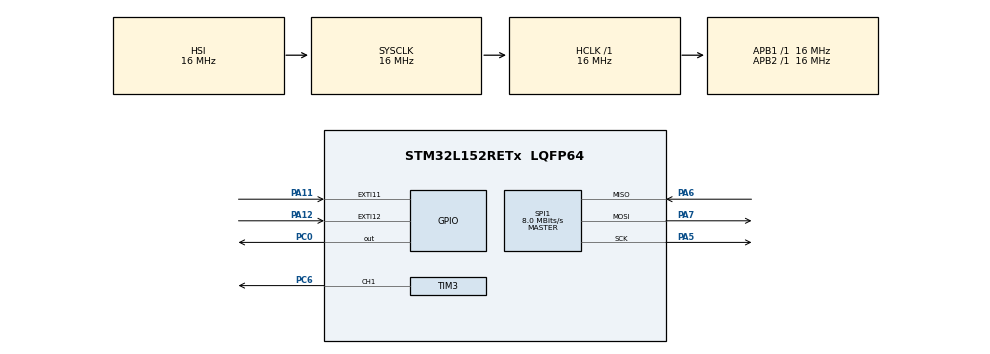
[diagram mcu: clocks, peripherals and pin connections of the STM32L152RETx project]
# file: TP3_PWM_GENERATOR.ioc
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Mcu.Family=STM32L1
Mcu.Name=STM32L152RETx
Mcu.Package=LQFP64
NVIC.EXTI15_10_IRQn=true\:0\:0\:false\:false\:true\:true\:true\:true
NVIC.PriorityGroup=NVIC_PRIORITYGROUP_4
NVIC.TIM2_IRQn=true\:0\:0\:false\:false\:true\:true\:true\:true
NVIC.TIM3_IRQn=true\:0\:0\:false\:false\:true\:true\:true\:true
PA11.Signal=GPXTI11
PA12.Signal=GPXTI12
PA5.Mode=Full_Duplex_Master
PA5.Signal=SPI1_SCK
PA6.Mode=Full_Duplex_Master
PA6.Signal=SPI1_MISO
PA7.Mode=Full_Duplex_Master
PA7.Signal=SPI1_MOSI
PC0.Signal=GPIO_Output
PC6.Signal=S_TIM3_CH1
ProjectManager.HeapSize=0x200
ProjectManager.StackSize=0x400
ProjectManager.TargetToolchain=STM32CubeIDE
RCC.AHBFreq_Value=16000000
RCC.APB1Freq_Value=16000000
RCC.APB1TimFreq_Value=16000000
RCC.APB2Freq_Value=16000000
RCC.APB2TimFreq_Value=16000000
RCC.HCLKFreq_Value=16000000
RCC.HSE_VALUE=24000000
RCC.HSI_VALUE=16000000
RCC.LSE_VALUE=32768
RCC.MSI_VALUE=2097000
RCC.SYSCLKFreq_VALUE=16000000
RCC.SYSCLKSource=RCC_SYSCLKSOURCE_HSI
RCC.VCOOutputFreq_Value=48000000
SH.S_TIM3_CH1.0=TIM3_CH1,PWM Generation1 CH1
SPI1.CalculateBaudRate=8.0 MBits/s
SPI1.Direction=SPI_DIRECTION_2LINES
SPI1.Mode=SPI_MODE_MASTER
SPI1.VirtualType=VM_MASTER
TIM2.AutoReloadPreload=TIM_AUTORELOAD_PRELOAD_ENABLE
TIM2.Period=16000-1
TIM2.Prescaler=1000-1
TIM3.AutoReloadPreload=TIM_AUTORELOAD_PRELOAD_ENABLE
TIM3.Channel-PWM\ Generation1\ CH1=TIM_CHANNEL_1
TIM3.Period=1000-1
TIM3.Prescaler=64-1
TIM3.Pulse-PWM\ Generation1\ CH1=500
VP_TIM2_VS_ClockSourceINT.Mode=Internal
VP_TIM3_VS_ClockSourceINT.Mode=Internal
board=custom

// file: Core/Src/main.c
/* USER CODE BEGIN Header */
/**
  ******************************************************************************
  * @file           : main.c
  * @brief          : Main program body
  ******************************************************************************
  * @attention
  *
  * Copyright (c) 2025 STMicroelectronics.
  * All rights reserved.
  *
  * This software is licensed under terms that can be found in the LICENSE file
  * in the root directory of this software component.
  * If no LICENSE file comes with this software, it is provided AS-IS.
  *
  ******************************************************************************
  */
/* USER CODE END Header */
#include "main.h"

/* USER CODE BEGIN Includes */
#include "max7219.h"

/* USER CODE END Includes */

SPI_HandleTypeDef hspi1;

TIM_HandleTypeDef htim2;
TIM_HandleTypeDef htim3;

void SystemClock_Config(void);
static void MX_GPIO_Init(void);
static void MX_SPI1_Init(void);
static void MX_TIM2_Init(void);
static void MX_TIM3_Init(void);

int main(void)
{

  /* MCU Configuration--------------------------------------------------------*/

  /* Reset of all peripherals, Initializes the Flash interface and the Systick. */
  HAL_Init();

  /* Configure the system clock */
  SystemClock_Config();

  /* Initialize all configured peripherals */
  MX_GPIO_Init();
  MX_SPI1_Init();
  MX_TIM2_Init();
  MX_TIM3_Init();
  /* USER CODE BEGIN 2 */
  MAX7219_Init();
  HAL_TIM_PWM_Start(&htim3, TIM_CHANNEL_1);

  /* USER CODE END 2 */

  /* Infinite loop */
  /* USER CODE BEGIN WHILE */
  MAX7219_Clear();
  while (1)
  {
    /* USER CODE END WHILE */

 }
}

void SystemClock_Config(void)
{
  RCC_OscInitTypeDef RCC_OscInitStruct = {0};
  RCC_ClkInitTypeDef RCC_ClkInitStruct = {0};

  /** Configure the main internal regulator output voltage
  */
  __HAL_PWR_VOLTAGESCALING_CONFIG(PWR_REGULATOR_VOLTAGE_SCALE1);

  /** Initializes the RCC Oscillators according to the specified parameters
  * in the RCC_OscInitTypeDef structure.
  */
  RCC_OscInitStruct.OscillatorType = RCC_OSCILLATORTYPE_HSI;
  RCC_OscInitStruct.HSIState = RCC_HSI_ON;
  RCC_OscInitStruct.HSICalibrationValue = RCC_HSICALIBRATION_DEFAULT;
  RCC_OscInitStruct.PLL.PLLState = RCC_PLL_NONE;
  if (HAL_RCC_OscConfig(&RCC_OscInitStruct) != HAL_OK)
  {
    Error_Handler();
  }

  /** Initializes the CPU, AHB and APB buses clocks
  */
  RCC_ClkInitStruct.ClockType = RCC_CLOCKTYPE_HCLK|RCC_CLOCKTYPE_SYSCLK
                              |RCC_CLOCKTYPE_PCLK1|RCC_CLOCKTYPE_PCLK2;
  RCC_ClkInitStruct.SYSCLKSource = RCC_SYSCLKSOURCE_HSI;
  RCC_ClkInitStruct.AHBCLKDivider = RCC_SYSCLK_DIV1;
  RCC_ClkInitStruct.APB1CLKDivider = RCC_HCLK_DIV1;
  RCC_ClkInitStruct.APB2CLKDivider = RCC_HCLK_DIV1;

  if (HAL_RCC_ClockConfig(&RCC_ClkInitStruct, FLASH_LATENCY_0) != HAL_OK)
  {
    Error_Handler();
  }
}

static void MX_SPI1_Init(void)
{

  /* SPI1 parameter configuration*/
  hspi1.Instance = SPI1;
  hspi1.Init.Mode = SPI_MODE_MASTER;
  hspi1.Init.Direction = SPI_DIRECTION_2LINES;
  hspi1.Init.DataSize = SPI_DATASIZE_8BIT;
  hspi1.Init.CLKPolarity = SPI_POLARITY_LOW;
  hspi1.Init.CLKPhase = SPI_PHASE_1EDGE;
  hspi1.Init.NSS = SPI_NSS_SOFT;
  hspi1.Init.BaudRatePrescaler = SPI_BAUDRATEPRESCALER_2;
  hspi1.Init.FirstBit = SPI_FIRSTBIT_MSB;
  hspi1.Init.TIMode = SPI_TIMODE_DISABLE;
  hspi1.Init.CRCCalculation = SPI_CRCCALCULATION_DISABLE;
  hspi1.Init.CRCPolynomial = 10;
  if (HAL_SPI_Init(&hspi1) != HAL_OK)
  {
    Error_Handler();
  }

}

static void MX_TIM2_Init(void)
{

  TIM_ClockConfigTypeDef sClockSourceConfig = {0};
  TIM_MasterConfigTypeDef sMasterConfig = {0};

  htim2.Instance = TIM2;
  htim2.Init.Prescaler = 1000-1;
  htim2.Init.CounterMode = TIM_COUNTERMODE_UP;
  htim2.Init.Period = 16000-1;
  htim2.Init.ClockDivision = TIM_CLOCKDIVISION_DIV1;
  htim2.Init.AutoReloadPreload = TIM_AUTORELOAD_PRELOAD_ENABLE;
  if (HAL_TIM_Base_Init(&htim2) != HAL_OK)
  {
    Error_Handler();
  }
  sClockSourceConfig.ClockSource = TIM_CLOCKSOURCE_INTERNAL;
  if (HAL_TIM_ConfigClockSource(&htim2, &sClockSourceConfig) != HAL_OK)
  {
    Error_Handler();
  }
  sMasterConfig.MasterOutputTrigger = TIM_TRGO_RESET;
  sMasterConfig.MasterSlaveMode = TIM_MASTERSLAVEMODE_DISABLE;
  if (HAL_TIMEx_MasterConfigSynchronization(&htim2, &sMasterConfig) != HAL_OK)
  {
    Error_Handler();
  }

}

static void MX_TIM3_Init(void)
{

  TIM_ClockConfigTypeDef sClockSourceConfig = {0};
  TIM_MasterConfigTypeDef sMasterConfig = {0};
  TIM_OC_InitTypeDef sConfigOC = {0};

  htim3.Instance = TIM3;
  htim3.Init.Prescaler = 64-1;
  htim3.Init.CounterMode = TIM_COUNTERMODE_UP;
  htim3.Init.Period = 1000-1;
  htim3.Init.ClockDivision = TIM_CLOCKDIVISION_DIV1;
  htim3.Init.AutoReloadPreload = TIM_AUTORELOAD_PRELOAD_ENABLE;
  if (HAL_TIM_Base_Init(&htim3) != HAL_OK)
  {
    Error_Handler();
  }
  sClockSourceConfig.ClockSource = TIM_CLOCKSOURCE_INTERNAL;
  if (HAL_TIM_ConfigClockSource(&htim3, &sClockSourceConfig) != HAL_OK)
  {
    Error_Handler();
  }
  if (HAL_TIM_PWM_Init(&htim3) != HAL_OK)
  {
    Error_Handler();
  }
  sMasterConfig.MasterOutputTrigger = TIM_TRGO_RESET;
  sMasterConfig.MasterSlaveMode = TIM_MASTERSLAVEMODE_DISABLE;
  if (HAL_TIMEx_MasterConfigSynchronization(&htim3, &sMasterConfig) != HAL_OK)
  {
    Error_Handler();
  }
  sConfigOC.OCMode = TIM_OCMODE_PWM1;
  sConfigOC.Pulse = 500;
  sConfigOC.OCPolarity = TIM_OCPOLARITY_HIGH;
  sConfigOC.OCFastMode = TIM_OCFAST_DISABLE;
  if (HAL_TIM_PWM_ConfigChannel(&htim3, &sConfigOC, TIM_CHANNEL_1) != HAL_OK)
  {
    Error_Handler();
  }
  HAL_TIM_MspPostInit(&htim3);

}

static void MX_GPIO_Init(void)
{
  GPIO_InitTypeDef GPIO_InitStruct = {0};

  /* GPIO Ports Clock Enable */
  __HAL_RCC_GPIOC_CLK_ENABLE();
  __HAL_RCC_GPIOA_CLK_ENABLE();

  /*Configure GPIO pin Output Level */
  HAL_GPIO_WritePin(GPIOC, GPIO_PIN_0, GPIO_PIN_RESET);

  /*Configure GPIO pin : PC0 */
  GPIO_InitStruct.Pin = GPIO_PIN_0;
  GPIO_InitStruct.Mode = GPIO_MODE_OUTPUT_PP;
  GPIO_InitStruct.Pull = GPIO_NOPULL;
  GPIO_InitStruct.Speed = GPIO_SPEED_FREQ_LOW;
  HAL_GPIO_Init(GPIOC, &GPIO_InitStruct);

  /*Configure GPIO pins : PA11 PA12 */
  GPIO_InitStruct.Pin = GPIO_PIN_11|GPIO_PIN_12;
  GPIO_InitStruct.Mode = GPIO_MODE_IT_RISING;
  GPIO_InitStruct.Pull = GPIO_NOPULL;
  HAL_GPIO_Init(GPIOA, &GPIO_InitStruct);

  /* EXTI interrupt init*/
  HAL_NVIC_SetPriority(EXTI15_10_IRQn, 0, 0);
  HAL_NVIC_EnableIRQ(EXTI15_10_IRQn);

}

void Error_Handler(void)
{
  __disable_irq();
  while (1)
  {
  }
}
